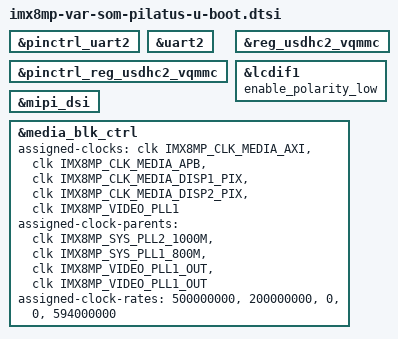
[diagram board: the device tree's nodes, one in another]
// SPDX-License-Identifier: GPL-2.0+
/*
 * Copyright 2019 NXP
 * Copyright 2020-2024 Variscite Ltd.
 */

#include "imx8mp-var-common-u-boot.dtsi"

&pinctrl_uart2 {
	bootph-pre-ram;
};

&uart2 {
	bootph-pre-ram;
};

&pinctrl_reg_usdhc2_vqmmc {
	bootph-pre-ram;
};

&reg_usdhc2_vqmmc {
	bootph-pre-ram;
};

&lcdif1 {
	enable_polarity_low;
	/delete-property/ assigned-clocks;
	/delete-property/ assigned-clock-parents;
	/delete-property/ assigned-clock-rates;
};

&mipi_dsi {
	/delete-property/ assigned-clocks;
	/delete-property/ assigned-clock-parents;
	/delete-property/ assigned-clock-rates;
};

&media_blk_ctrl {
	assigned-clocks = <&clk IMX8MP_CLK_MEDIA_AXI>,
			  <&clk IMX8MP_CLK_MEDIA_APB>,
			  <&clk IMX8MP_CLK_MEDIA_DISP1_PIX>,
			  <&clk IMX8MP_CLK_MEDIA_DISP2_PIX>,
			  <&clk IMX8MP_VIDEO_PLL1>;
	assigned-clock-parents = <&clk IMX8MP_SYS_PLL2_1000M>,
				 <&clk IMX8MP_SYS_PLL1_800M>,
				 <&clk IMX8MP_VIDEO_PLL1_OUT>,
				 <&clk IMX8MP_VIDEO_PLL1_OUT>;
	assigned-clock-rates = <500000000>, <200000000>,
				 <0>, <0>, <594000000>;
};
